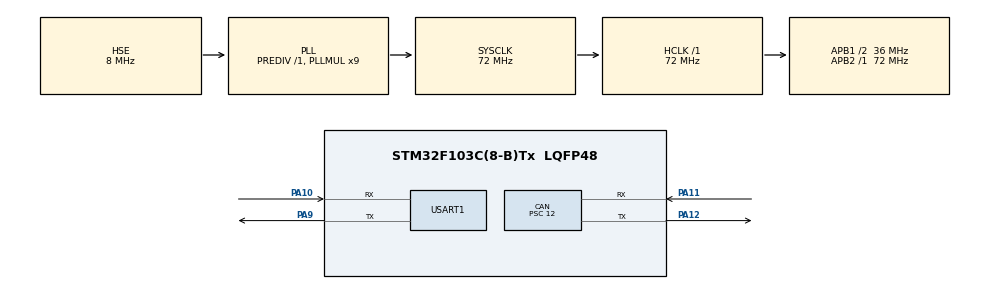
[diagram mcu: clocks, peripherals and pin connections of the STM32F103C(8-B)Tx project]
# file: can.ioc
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CAN.BS1=CAN_BS1_3TQ
CAN.BS2=CAN_BS2_2TQ
CAN.CalculateTimeBit=2000
CAN.CalculateTimeQuantum=333.33333333333337
CAN.Mode=CAN_MODE_LOOPBACK
CAN.Prescaler=12
CAN.SJW=CAN_SJW_1TQ
Mcu.Family=STM32F1
Mcu.Name=STM32F103C(8-B)Tx
Mcu.Package=LQFP48
NVIC.PriorityGroup=NVIC_PRIORITYGROUP_4
NVIC.USART1_IRQn=true\:1\:0\:true\:false\:true\:true\:true
NVIC.USB_LP_CAN1_RX0_IRQn=true\:0\:0\:false\:false\:true\:true\:true
PA10.Mode=Asynchronous
PA10.Signal=USART1_RX
PA11.Mode=Master
PA11.Signal=CAN_RX
PA12.Mode=Master
PA12.Signal=CAN_TX
PA13.Mode=Serial_Wire
PA13.Signal=SYS_JTMS-SWDIO
PA14.Mode=Serial_Wire
PA14.Signal=SYS_JTCK-SWCLK
PA9.Mode=Asynchronous
PA9.Signal=USART1_TX
PD0-OSC_IN.Mode=HSE-External-Oscillator
PD0-OSC_IN.Signal=RCC_OSC_IN
PD1-OSC_OUT.Mode=HSE-External-Oscillator
PD1-OSC_OUT.Signal=RCC_OSC_OUT
ProjectManager.HeapSize=0x200
ProjectManager.StackSize=0x400
ProjectManager.TargetToolchain=MDK-ARM V5
RCC.AHBFreq_Value=72000000
RCC.APB1CLKDivider=RCC_HCLK_DIV2
RCC.APB1Freq_Value=36000000
RCC.APB1TimFreq_Value=72000000
RCC.APB2Freq_Value=72000000
RCC.APB2TimFreq_Value=72000000
RCC.HCLKFreq_Value=72000000
RCC.PLLMUL=RCC_PLL_MUL9
RCC.PLLSourceVirtual=RCC_PLLSOURCE_HSE
RCC.SYSCLKFreq_VALUE=72000000
RCC.SYSCLKSource=RCC_SYSCLKSOURCE_PLLCLK
RCC.USBFreq_Value=72000000
USART1.VirtualMode=VM_ASYNC
board=custom

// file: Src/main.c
/* USER CODE BEGIN Header */
/**
  ******************************************************************************
  * @file           : main.c
  * @brief          : Main program body
  ******************************************************************************
  * @attention
  *
  * <h2><center>&copy; Copyright (c) 2019 STMicroelectronics.
  * All rights reserved.</center></h2>
  *
  * This software component is licensed by ST under BSD 3-Clause license,
  * the "License"; You may not use this file except in compliance with the
  * License. You may obtain a copy of the License at:
  *                        opensource.org/licenses/BSD-3-Clause
  *
  ******************************************************************************
  */
/* USER CODE END Header */

#include "main.h"
#include "can.h"
#include "usart.h"
#include "gpio.h"

void SystemClock_Config(void);

int main(void)
{
  /* USER CODE BEGIN 1 */
	uint8_t data[8]={1,2,3,4,5,6,7,8};
  /* USER CODE END 1 */

  /* MCU Configuration--------------------------------------------------------*/

  /* Reset of all peripherals, Initializes the Flash interface and the Systick. */
  HAL_Init();

  /* Configure the system clock */
  SystemClock_Config();

  /* Initialize all configured peripherals */
  MX_GPIO_Init();
  MX_CAN_Init();
  MX_USART1_UART_Init();
  /* USER CODE BEGIN 2 */
	CAN1_Config();
  /* USER CODE END 2 */
  /* Infinite loop */
  while (1)
  {

    /* USER CODE BEGIN 3 */
	  Can_TxMessage(0,0x222,8,data);
	  HAL_Delay(1000);
  }
  /* USER CODE END 3 */
}

void SystemClock_Config(void)
{
  RCC_OscInitTypeDef RCC_OscInitStruct = {0};
  RCC_ClkInitTypeDef RCC_ClkInitStruct = {0};

  /** Initializes the CPU, AHB and APB busses clocks
  */
  RCC_OscInitStruct.OscillatorType = RCC_OSCILLATORTYPE_HSE;
  RCC_OscInitStruct.HSEState = RCC_HSE_ON;
  RCC_OscInitStruct.HSEPredivValue = RCC_HSE_PREDIV_DIV1;
  RCC_OscInitStruct.HSIState = RCC_HSI_ON;
  RCC_OscInitStruct.PLL.PLLState = RCC_PLL_ON;
  RCC_OscInitStruct.PLL.PLLSource = RCC_PLLSOURCE_HSE;
  RCC_OscInitStruct.PLL.PLLMUL = RCC_PLL_MUL9;
  if (HAL_RCC_OscConfig(&RCC_OscInitStruct) != HAL_OK)
  {
    Error_Handler();
  }
  /** Initializes the CPU, AHB and APB busses clocks
  */
  RCC_ClkInitStruct.ClockType = RCC_CLOCKTYPE_HCLK|RCC_CLOCKTYPE_SYSCLK
                              |RCC_CLOCKTYPE_PCLK1|RCC_CLOCKTYPE_PCLK2;
  RCC_ClkInitStruct.SYSCLKSource = RCC_SYSCLKSOURCE_PLLCLK;
  RCC_ClkInitStruct.AHBCLKDivider = RCC_SYSCLK_DIV1;
  RCC_ClkInitStruct.APB1CLKDivider = RCC_HCLK_DIV2;
  RCC_ClkInitStruct.APB2CLKDivider = RCC_HCLK_DIV1;

  if (HAL_RCC_ClockConfig(&RCC_ClkInitStruct, FLASH_LATENCY_2) != HAL_OK)
  {
    Error_Handler();
  }
}

void Error_Handler(void)
{
}

/************************ (C) COPYRIGHT STMicroelectronics *****END OF FILE****/
